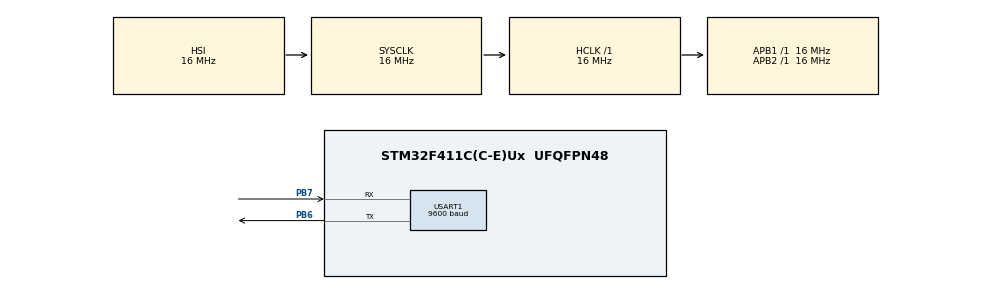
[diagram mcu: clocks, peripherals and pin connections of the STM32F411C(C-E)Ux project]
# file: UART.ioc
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Mcu.Family=STM32F4
Mcu.Name=STM32F411C(C-E)Ux
Mcu.Package=UFQFPN48
NVIC.PriorityGroup=NVIC_PRIORITYGROUP_4
PA13.Mode=Serial_Wire
PA13.Signal=SYS_JTMS-SWDIO
PA14.Mode=Serial_Wire
PA14.Signal=SYS_JTCK-SWCLK
PB6.Mode=Asynchronous
PB6.Signal=USART1_TX
PB7.Mode=Asynchronous
PB7.Signal=USART1_RX
ProjectManager.HeapSize=0x200
ProjectManager.StackSize=0x400
ProjectManager.TargetToolchain=STM32CubeIDE
RCC.AHBFreq_Value=16000000
RCC.APB1Freq_Value=16000000
RCC.APB2Freq_Value=16000000
RCC.CortexFreq_Value=16000000
RCC.HSE_VALUE=25000000
RCC.HSI_VALUE=16000000
RCC.LSE_VALUE=32768
RCC.SYSCLKFreq_VALUE=16000000
RCC.VCOOutputFreq_Value=192000000
USART1.BaudRate=9600
USART1.Mode=MODE_TX_RX
USART1.StopBits=STOPBITS_2
USART1.VirtualMode=VM_ASYNC
board=custom

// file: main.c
/* USER CODE BEGIN Header */
/**
  ******************************************************************************
  * @file           : main.c
  * @brief          : Main program body
  ******************************************************************************
  * @attention
  *
  * <h2><center>&copy; Copyright (c) 2021 STMicroelectronics.
  * All rights reserved.</center></h2>
  *
  * This software component is licensed by ST under BSD 3-Clause license,
  * the "License"; You may not use this file except in compliance with the
  * License. You may obtain a copy of the License at:
  *                        opensource.org/licenses/BSD-3-Clause
  *
  ******************************************************************************
  */
/* USER CODE END Header */
#include "main.h"

/* USER CODE BEGIN Includes */
#include "stdio.h"
/* USER CODE END Includes */

UART_HandleTypeDef huart1;

void SystemClock_Config(void);
static void MX_GPIO_Init(void);
static void MX_USART1_UART_Init(void);

/* USER CODE BEGIN 0 */
uint8_t cmd_end[3] = {0xFF, 0xFF, 0xFF};

void NextionSendString(char *ID, char *string)
{
	char buf[50];
	int len = sprintf(buf, "%s.txt=\"%s\"\n", ID, string);
	HAL_UART_Transmit(&huart1, (uint8_t *)buf, len, 1000);
	HAL_UART_Transmit(&huart1, cmd_end, 0, 100);
}
/* USER CODE END 0 */

int main(void)
{

  /* MCU Configuration--------------------------------------------------------*/

  /* Reset of all peripherals, Initializes the Flash interface and the Systick. */
  HAL_Init();

  /* Configure the system clock */
  SystemClock_Config();

  /* Initialize all configured peripherals */
  MX_GPIO_Init();
  MX_USART1_UART_Init();

  /* Infinite loop */
  /* USER CODE BEGIN WHILE */
  while (1)
  {
	  NextionSendString("t0", "bye");
	  NextionSendString("t1", "bye");
	  HAL_Delay(1000);
    /* USER CODE END WHILE */

  }
}

void SystemClock_Config(void)
{
  RCC_OscInitTypeDef RCC_OscInitStruct = {0};
  RCC_ClkInitTypeDef RCC_ClkInitStruct = {0};

  /** Configure the main internal regulator output voltage
  */
  __HAL_RCC_PWR_CLK_ENABLE();
  __HAL_PWR_VOLTAGESCALING_CONFIG(PWR_REGULATOR_VOLTAGE_SCALE1);
  /** Initializes the RCC Oscillators according to the specified parameters
  * in the RCC_OscInitTypeDef structure.
  */
  RCC_OscInitStruct.OscillatorType = RCC_OSCILLATORTYPE_HSI;
  RCC_OscInitStruct.HSIState = RCC_HSI_ON;
  RCC_OscInitStruct.HSICalibrationValue = RCC_HSICALIBRATION_DEFAULT;
  RCC_OscInitStruct.PLL.PLLState = RCC_PLL_NONE;
  if (HAL_RCC_OscConfig(&RCC_OscInitStruct) != HAL_OK)
  {
    Error_Handler();
  }
  /** Initializes the CPU, AHB and APB buses clocks
  */
  RCC_ClkInitStruct.ClockType = RCC_CLOCKTYPE_HCLK|RCC_CLOCKTYPE_SYSCLK
                              |RCC_CLOCKTYPE_PCLK1|RCC_CLOCKTYPE_PCLK2;
  RCC_ClkInitStruct.SYSCLKSource = RCC_SYSCLKSOURCE_HSI;
  RCC_ClkInitStruct.AHBCLKDivider = RCC_SYSCLK_DIV1;
  RCC_ClkInitStruct.APB1CLKDivider = RCC_HCLK_DIV1;
  RCC_ClkInitStruct.APB2CLKDivider = RCC_HCLK_DIV1;

  if (HAL_RCC_ClockConfig(&RCC_ClkInitStruct, FLASH_LATENCY_0) != HAL_OK)
  {
    Error_Handler();
  }
}

static void MX_USART1_UART_Init(void)
{

  huart1.Instance = USART1;
  huart1.Init.BaudRate = 9600;
  huart1.Init.WordLength = UART_WORDLENGTH_8B;
  huart1.Init.StopBits = UART_STOPBITS_2;
  huart1.Init.Parity = UART_PARITY_NONE;
  huart1.Init.Mode = UART_MODE_TX_RX;
  huart1.Init.HwFlowCtl = UART_HWCONTROL_NONE;
  huart1.Init.OverSampling = UART_OVERSAMPLING_16;
  if (HAL_UART_Init(&huart1) != HAL_OK)
  {
    Error_Handler();
  }

}

static void MX_GPIO_Init(void)
{

  /* GPIO Ports Clock Enable */
  __HAL_RCC_GPIOA_CLK_ENABLE();
  __HAL_RCC_GPIOB_CLK_ENABLE();

}

void Error_Handler(void)
{
  __disable_irq();
  while (1)
  {
  }
}

/************************ (C) COPYRIGHT STMicroelectronics *****END OF FILE****/
